VERSION ""

NS_ :

BS_:

BU_: XXX EPS

CM_ "Toyota Prius 5th Gen TSS3 test DBC v1 from user logs";
CM_ "Based on observed CAN/CAN-FD frames from uploaded logs and Toyota reference naming.";

CM_ BO_ 48 "32-byte PT/body candidate frame";
CM_ BO_ 144 "32-byte PT/body candidate frame";
CM_ BO_ 201 "32-byte PT/body candidate frame";
CM_ BO_ 213 "8-byte status candidate frame";
CM_ BO_ 215 "32-byte PT/body candidate frame";
CM_ BO_ 277 "8-byte PT/body candidate frame";
CM_ BO_ 278 "8-byte PT/body candidate frame";
CM_ BO_ 295 "8-byte PT/body candidate frame";
CM_ BO_ 392 "64-byte CAN-FD TRACK_A candidate";
CM_ BO_ 393 "64-byte CAN-FD TRACK_A candidate";
CM_ BO_ 394 "64-byte CAN-FD TRACK_A candidate";
CM_ BO_ 395 "64-byte CAN-FD TRACK_A candidate";
CM_ BO_ 396 "48-byte CAN-FD TRACK_A candidate";
CM_ BO_ 416 "48-byte CAN-FD TRACK_B candidate";
CM_ BO_ 512 "64-byte CAN-FD object/status candidate";
CM_ BO_ 513 "64-byte CAN-FD object/status candidate";

BO_ 48 PT_STATE_0x030: 32 XXX
 SG_ PT030_B00 : 0|8@0+ (1,0) [0|255] "" XXX
 SG_ PT030_B01 : 8|8@0+ (1,0) [0|255] "" XXX
 SG_ PT030_B02 : 16|8@0+ (1,0) [0|255] "" XXX
 SG_ PT030_B03 : 24|8@0+ (1,0) [0|255] "" XXX
 SG_ PT030_B04 : 32|8@0+ (1,0) [0|255] "" XXX
 SG_ PT030_B05 : 40|8@0+ (1,0) [0|255] "" XXX
 SG_ PT030_B06 : 48|8@0+ (1,0) [0|255] "" XXX
 SG_ PT030_B07 : 56|8@0+ (1,0) [0|255] "" XXX
 SG_ PT030_B08 : 64|8@0+ (1,0) [0|255] "" XXX
 SG_ PT030_B09 : 72|8@0+ (1,0) [0|255] "" XXX
 SG_ PT030_B10 : 80|8@0+ (1,0) [0|255] "" XXX
 SG_ PT030_B11 : 88|8@0+ (1,0) [0|255] "" XXX
 SG_ PT030_B12 : 96|8@0+ (1,0) [0|255] "" XXX
 SG_ PT030_B13 : 104|8@0+ (1,0) [0|255] "" XXX
 SG_ PT030_B14 : 112|8@0+ (1,0) [0|255] "" XXX
 SG_ PT030_B15 : 120|8@0+ (1,0) [0|255] "" XXX
 SG_ PT030_B16 : 128|8@0+ (1,0) [0|255] "" XXX
 SG_ PT030_B17 : 136|8@0+ (1,0) [0|255] "" XXX
 SG_ PT030_B18 : 144|8@0+ (1,0) [0|255] "" XXX
 SG_ PT030_B19 : 152|8@0+ (1,0) [0|255] "" XXX
 SG_ PT030_B20 : 160|8@0+ (1,0) [0|255] "" XXX
 SG_ PT030_B21 : 168|8@0+ (1,0) [0|255] "" XXX
 SG_ PT030_B22 : 176|8@0+ (1,0) [0|255] "" XXX
 SG_ PT030_B23 : 184|8@0+ (1,0) [0|255] "" XXX
 SG_ PT030_B24 : 192|8@0+ (1,0) [0|255] "" XXX
 SG_ PT030_B25 : 200|8@0+ (1,0) [0|255] "" XXX
 SG_ PT030_B26 : 208|8@0+ (1,0) [0|255] "" XXX
 SG_ PT030_B27 : 216|8@0+ (1,0) [0|255] "" XXX
 SG_ PT030_TAIL : 224|32@0+ (1,0) [0|4294967295] "" XXX

BO_ 144 PT_STATE_0x090: 32 XXX
 SG_ PT090_B00 : 0|8@0+ (1,0) [0|255] "" XXX
 SG_ PT090_B01 : 8|8@0+ (1,0) [0|255] "" XXX
 SG_ PT090_B02 : 16|8@0+ (1,0) [0|255] "" XXX
 SG_ PT090_B03 : 24|8@0+ (1,0) [0|255] "" XXX
 SG_ PT090_B04 : 32|8@0+ (1,0) [0|255] "" XXX
 SG_ PT090_B05 : 40|8@0+ (1,0) [0|255] "" XXX
 SG_ PT090_B06 : 48|8@0+ (1,0) [0|255] "" XXX
 SG_ PT090_B07 : 56|8@0+ (1,0) [0|255] "" XXX
 SG_ PT090_B08 : 64|8@0+ (1,0) [0|255] "" XXX
 SG_ PT090_B09 : 72|8@0+ (1,0) [0|255] "" XXX
 SG_ PT090_B10 : 80|8@0+ (1,0) [0|255] "" XXX
 SG_ PT090_B11 : 88|8@0+ (1,0) [0|255] "" XXX
 SG_ PT090_B12 : 96|8@0+ (1,0) [0|255] "" XXX
 SG_ PT090_B13 : 104|8@0+ (1,0) [0|255] "" XXX
 SG_ PT090_B14 : 112|8@0+ (1,0) [0|255] "" XXX
 SG_ PT090_B15 : 120|8@0+ (1,0) [0|255] "" XXX
 SG_ PT090_B16 : 128|8@0+ (1,0) [0|255] "" XXX
 SG_ PT090_B17 : 136|8@0+ (1,0) [0|255] "" XXX
 SG_ PT090_B18 : 144|8@0+ (1,0) [0|255] "" XXX
 SG_ PT090_B19 : 152|8@0+ (1,0) [0|255] "" XXX
 SG_ PT090_B20 : 160|8@0+ (1,0) [0|255] "" XXX
 SG_ PT090_B21 : 168|8@0+ (1,0) [0|255] "" XXX
 SG_ PT090_B22 : 176|8@0+ (1,0) [0|255] "" XXX
 SG_ PT090_B23 : 184|8@0+ (1,0) [0|255] "" XXX
 SG_ PT090_B24 : 192|8@0+ (1,0) [0|255] "" XXX
 SG_ PT090_B25 : 200|8@0+ (1,0) [0|255] "" XXX
 SG_ PT090_B26 : 208|8@0+ (1,0) [0|255] "" XXX
 SG_ PT090_B27 : 216|8@0+ (1,0) [0|255] "" XXX
 SG_ PT090_TAIL : 224|32@0+ (1,0) [0|4294967295] "" XXX

BO_ 201 PT_STATE_0x0C9: 32 XXX
 SG_ PT0C9_B00 : 0|8@0+ (1,0) [0|255] "" XXX
 SG_ PT0C9_B01 : 8|8@0+ (1,0) [0|255] "" XXX
 SG_ PT0C9_B02 : 16|8@0+ (1,0) [0|255] "" XXX
 SG_ PT0C9_B03 : 24|8@0+ (1,0) [0|255] "" XXX
 SG_ PT0C9_B04 : 32|8@0+ (1,0) [0|255] "" XXX
 SG_ PT0C9_B05 : 40|8@0+ (1,0) [0|255] "" XXX
 SG_ PT0C9_B06 : 48|8@0+ (1,0) [0|255] "" XXX
 SG_ PT0C9_B07 : 56|8@0+ (1,0) [0|255] "" XXX
 SG_ PT0C9_B08 : 64|8@0+ (1,0) [0|255] "" XXX
 SG_ PT0C9_B09 : 72|8@0+ (1,0) [0|255] "" XXX
 SG_ PT0C9_B10 : 80|8@0+ (1,0) [0|255] "" XXX
 SG_ PT0C9_B11 : 88|8@0+ (1,0) [0|255] "" XXX
 SG_ PT0C9_B12 : 96|8@0+ (1,0) [0|255] "" XXX
 SG_ PT0C9_B13 : 104|8@0+ (1,0) [0|255] "" XXX
 SG_ PT0C9_B14 : 112|8@0+ (1,0) [0|255] "" XXX
 SG_ PT0C9_B15 : 120|8@0+ (1,0) [0|255] "" XXX
 SG_ PT0C9_B16 : 128|8@0+ (1,0) [0|255] "" XXX
 SG_ PT0C9_B17 : 136|8@0+ (1,0) [0|255] "" XXX
 SG_ PT0C9_B18 : 144|8@0+ (1,0) [0|255] "" XXX
 SG_ PT0C9_B19 : 152|8@0+ (1,0) [0|255] "" XXX
 SG_ PT0C9_B20 : 160|8@0+ (1,0) [0|255] "" XXX
 SG_ PT0C9_B21 : 168|8@0+ (1,0) [0|255] "" XXX
 SG_ PT0C9_B22 : 176|8@0+ (1,0) [0|255] "" XXX
 SG_ PT0C9_B23 : 184|8@0+ (1,0) [0|255] "" XXX
 SG_ PT0C9_B24 : 192|8@0+ (1,0) [0|255] "" XXX
 SG_ PT0C9_B25 : 200|8@0+ (1,0) [0|255] "" XXX
 SG_ PT0C9_B26 : 208|8@0+ (1,0) [0|255] "" XXX
 SG_ PT0C9_B27 : 216|8@0+ (1,0) [0|255] "" XXX
 SG_ PT0C9_TAIL : 224|32@0+ (1,0) [0|4294967295] "" XXX

BO_ 213 STATUS_0x0D5: 8 XXX
 SG_ ST0D5_B0 : 0|8@0+ (1,0) [0|255] "" XXX
 SG_ ST0D5_B1 : 8|8@0+ (1,0) [0|255] "" XXX
 SG_ ST0D5_B2 : 16|8@0+ (1,0) [0|255] "" XXX
 SG_ ST0D5_B3 : 24|8@0+ (1,0) [0|255] "" XXX
 SG_ ST0D5_B4 : 32|8@0+ (1,0) [0|255] "" XXX
 SG_ ST0D5_B5 : 40|8@0+ (1,0) [0|255] "" XXX
 SG_ ST0D5_B6 : 48|8@0+ (1,0) [0|255] "" XXX
 SG_ ST0D5_B7 : 56|8@0+ (1,0) [0|255] "" XXX

BO_ 215 PT_STATE_0x0D7: 32 XXX
 SG_ PT0D7_B00 : 0|8@0+ (1,0) [0|255] "" XXX
 SG_ PT0D7_B01 : 8|8@0+ (1,0) [0|255] "" XXX
 SG_ PT0D7_B02 : 16|8@0+ (1,0) [0|255] "" XXX
 SG_ PT0D7_B03 : 24|8@0+ (1,0) [0|255] "" XXX
 SG_ PT0D7_B04 : 32|8@0+ (1,0) [0|255] "" XXX
 SG_ PT0D7_B05 : 40|8@0+ (1,0) [0|255] "" XXX
 SG_ PT0D7_B06 : 48|8@0+ (1,0) [0|255] "" XXX
 SG_ PT0D7_B07 : 56|8@0+ (1,0) [0|255] "" XXX
 SG_ PT0D7_B08 : 64|8@0+ (1,0) [0|255] "" XXX
 SG_ PT0D7_B09 : 72|8@0+ (1,0) [0|255] "" XXX
 SG_ PT0D7_B10 : 80|8@0+ (1,0) [0|255] "" XXX
 SG_ PT0D7_B11 : 88|8@0+ (1,0) [0|255] "" XXX
 SG_ PT0D7_B12 : 96|8@0+ (1,0) [0|255] "" XXX
 SG_ PT0D7_B13 : 104|8@0+ (1,0) [0|255] "" XXX
 SG_ PT0D7_B14 : 112|8@0+ (1,0) [0|255] "" XXX
 SG_ PT0D7_B15 : 120|8@0+ (1,0) [0|255] "" XXX
 SG_ PT0D7_B16 : 128|8@0+ (1,0) [0|255] "" XXX
 SG_ PT0D7_B17 : 136|8@0+ (1,0) [0|255] "" XXX
 SG_ PT0D7_B18 : 144|8@0+ (1,0) [0|255] "" XXX
 SG_ PT0D7_B19 : 152|8@0+ (1,0) [0|255] "" XXX
 SG_ PT0D7_B20 : 160|8@0+ (1,0) [0|255] "" XXX
 SG_ PT0D7_B21 : 168|8@0+ (1,0) [0|255] "" XXX
 SG_ PT0D7_B22 : 176|8@0+ (1,0) [0|255] "" XXX
 SG_ PT0D7_B23 : 184|8@0+ (1,0) [0|255] "" XXX
 SG_ PT0D7_B24 : 192|8@0+ (1,0) [0|255] "" XXX
 SG_ PT0D7_B25 : 200|8@0+ (1,0) [0|255] "" XXX
 SG_ PT0D7_B26 : 208|8@0+ (1,0) [0|255] "" XXX
 SG_ PT0D7_B27 : 216|8@0+ (1,0) [0|255] "" XXX
 SG_ PT0D7_TAIL : 224|32@0+ (1,0) [0|4294967295] "" XXX

BO_ 277 PT_STATUS_0x115: 8 XXX
 SG_ PT115_B0 : 0|8@0+ (1,0) [0|255] "" XXX
 SG_ PT115_B1 : 8|8@0+ (1,0) [0|255] "" XXX
 SG_ PT115_B2 : 16|8@0+ (1,0) [0|255] "" XXX
 SG_ PT115_B3 : 24|8@0+ (1,0) [0|255] "" XXX
 SG_ PT115_B4 : 32|8@0+ (1,0) [0|255] "" XXX
 SG_ PT115_B5 : 40|8@0+ (1,0) [0|255] "" XXX
 SG_ PT115_B6 : 48|8@0+ (1,0) [0|255] "" XXX
 SG_ PT115_B7 : 56|8@0+ (1,0) [0|255] "" XXX

BO_ 278 PT_STATUS_0x116: 8 XXX
 SG_ PT116_B0 : 0|8@0+ (1,0) [0|255] "" XXX
 SG_ PT116_B1 : 8|8@0+ (1,0) [0|255] "" XXX
 SG_ PT116_B2 : 16|8@0+ (1,0) [0|255] "" XXX
 SG_ PT116_B3 : 24|8@0+ (1,0) [0|255] "" XXX
 SG_ PT116_B4 : 32|8@0+ (1,0) [0|255] "" XXX
 SG_ PT116_B5 : 40|8@0+ (1,0) [0|255] "" XXX
 SG_ PT116_B6 : 48|8@0+ (1,0) [0|255] "" XXX
 SG_ PT116_B7 : 56|8@0+ (1,0) [0|255] "" XXX

BO_ 295 PT_STATUS_0x127: 8 XXX
 SG_ PT127_B0 : 0|8@0+ (1,0) [0|255] "" XXX
 SG_ PT127_B1 : 8|8@0+ (1,0) [0|255] "" XXX
 SG_ PT127_B2 : 16|8@0+ (1,0) [0|255] "" XXX
 SG_ PT127_B3 : 24|8@0+ (1,0) [0|255] "" XXX
 SG_ PT127_B4 : 32|8@0+ (1,0) [0|255] "" XXX
 SG_ PT127_B5 : 40|8@0+ (1,0) [0|255] "" XXX
 SG_ PT127_B6 : 48|8@0+ (1,0) [0|255] "" XXX
 SG_ PT127_B7 : 56|8@0+ (1,0) [0|255] "" XXX

BO_ 392 TRACK_A_FD_8: 64 XXX
 SG_ TRK188_B00 : 0|8@0+ (1,0) [0|255] "" XXX
 SG_ TRK188_B01 : 8|8@0+ (1,0) [0|255] "" XXX
 SG_ TRK188_B02 : 16|8@0+ (1,0) [0|255] "" XXX
 SG_ TRK188_B03 : 24|8@0+ (1,0) [0|255] "" XXX
 SG_ TRK188_B04 : 32|8@0+ (1,0) [0|255] "" XXX
 SG_ TRK188_B05 : 40|8@0+ (1,0) [0|255] "" XXX
 SG_ TRK188_B06 : 48|8@0+ (1,0) [0|255] "" XXX
 SG_ TRK188_B07 : 56|8@0+ (1,0) [0|255] "" XXX
 SG_ TRK188_B08 : 64|8@0+ (1,0) [0|255] "" XXX
 SG_ TRK188_B09 : 72|8@0+ (1,0) [0|255] "" XXX
 SG_ TRK188_B10 : 80|8@0+ (1,0) [0|255] "" XXX
 SG_ TRK188_B11 : 88|8@0+ (1,0) [0|255] "" XXX
 SG_ TRK188_B12 : 96|8@0+ (1,0) [0|255] "" XXX
 SG_ TRK188_B13 : 104|8@0+ (1,0) [0|255] "" XXX
 SG_ TRK188_B14 : 112|8@0+ (1,0) [0|255] "" XXX
 SG_ TRK188_B15 : 120|8@0+ (1,0) [0|255] "" XXX
 SG_ TRK188_B16 : 128|8@0+ (1,0) [0|255] "" XXX
 SG_ TRK188_B17 : 136|8@0+ (1,0) [0|255] "" XXX
 SG_ TRK188_B18 : 144|8@0+ (1,0) [0|255] "" XXX
 SG_ TRK188_B19 : 152|8@0+ (1,0) [0|255] "" XXX
 SG_ TRK188_B20 : 160|8@0+ (1,0) [0|255] "" XXX
 SG_ TRK188_B21 : 168|8@0+ (1,0) [0|255] "" XXX
 SG_ TRK188_B22 : 176|8@0+ (1,0) [0|255] "" XXX
 SG_ TRK188_B23 : 184|8@0+ (1,0) [0|255] "" XXX
 SG_ TRK188_B24 : 192|8@0+ (1,0) [0|255] "" XXX
 SG_ TRK188_B25 : 200|8@0+ (1,0) [0|255] "" XXX
 SG_ TRK188_B26 : 208|8@0+ (1,0) [0|255] "" XXX
 SG_ TRK188_B27 : 216|8@0+ (1,0) [0|255] "" XXX
 SG_ TRK188_B28 : 224|8@0+ (1,0) [0|255] "" XXX
 SG_ TRK188_B29 : 232|8@0+ (1,0) [0|255] "" XXX
 SG_ TRK188_B30 : 240|8@0+ (1,0) [0|255] "" XXX
 SG_ TRK188_B31 : 248|8@0+ (1,0) [0|255] "" XXX
 SG_ TRK188_B32 : 256|8@0+ (1,0) [0|255] "" XXX
 SG_ TRK188_B33 : 264|8@0+ (1,0) [0|255] "" XXX
 SG_ TRK188_B34 : 272|8@0+ (1,0) [0|255] "" XXX
 SG_ TRK188_B35 : 280|8@0+ (1,0) [0|255] "" XXX
 SG_ TRK188_B36 : 288|8@0+ (1,0) [0|255] "" XXX
 SG_ TRK188_B37 : 296|8@0+ (1,0) [0|255] "" XXX
 SG_ TRK188_B38 : 304|8@0+ (1,0) [0|255] "" XXX
 SG_ TRK188_B39 : 312|8@0+ (1,0) [0|255] "" XXX
 SG_ TRK188_B40 : 320|8@0+ (1,0) [0|255] "" XXX
 SG_ TRK188_B41 : 328|8@0+ (1,0) [0|255] "" XXX
 SG_ TRK188_B42 : 336|8@0+ (1,0) [0|255] "" XXX
 SG_ TRK188_B43 : 344|8@0+ (1,0) [0|255] "" XXX
 SG_ TRK188_B44 : 352|8@0+ (1,0) [0|255] "" XXX
 SG_ TRK188_B45 : 360|8@0+ (1,0) [0|255] "" XXX
 SG_ TRK188_B46 : 368|8@0+ (1,0) [0|255] "" XXX
 SG_ TRK188_B47 : 376|8@0+ (1,0) [0|255] "" XXX
 SG_ TRK188_B48 : 384|8@0+ (1,0) [0|255] "" XXX
 SG_ TRK188_B49 : 392|8@0+ (1,0) [0|255] "" XXX
 SG_ TRK188_B50 : 400|8@0+ (1,0) [0|255] "" XXX
 SG_ TRK188_B51 : 408|8@0+ (1,0) [0|255] "" XXX
 SG_ TRK188_B52 : 416|8@0+ (1,0) [0|255] "" XXX
 SG_ TRK188_B53 : 424|8@0+ (1,0) [0|255] "" XXX
 SG_ TRK188_B54 : 432|8@0+ (1,0) [0|255] "" XXX
 SG_ TRK188_B55 : 440|8@0+ (1,0) [0|255] "" XXX
 SG_ TRK188_B56 : 448|8@0+ (1,0) [0|255] "" XXX
 SG_ TRK188_B57 : 456|8@0+ (1,0) [0|255] "" XXX
 SG_ TRK188_B58 : 464|8@0+ (1,0) [0|255] "" XXX
 SG_ TRK188_B59 : 472|8@0+ (1,0) [0|255] "" XXX
 SG_ TRK188_TAIL : 480|32@1+ (1,0) [0|4294967295] "" XXX

BO_ 393 TRACK_A_FD_9: 64 XXX
 SG_ TRK189_PAYLOAD : 0|480@0+ (1,0) [0|0] "" XXX
 SG_ TRK189_TAIL : 480|32@1+ (1,0) [0|4294967295] "" XXX

BO_ 394 TRACK_A_FD_10: 64 XXX
 SG_ TRK18A_PAYLOAD : 0|480@0+ (1,0) [0|0] "" XXX
 SG_ TRK18A_TAIL : 480|32@1+ (1,0) [0|4294967295] "" XXX

BO_ 395 TRACK_A_FD_11: 64 XXX
 SG_ TRK18B_PAYLOAD : 0|480@0+ (1,0) [0|0] "" XXX
 SG_ TRK18B_TAIL : 480|32@1+ (1,0) [0|4294967295] "" XXX

BO_ 396 TRACK_A_FD_12: 48 XXX
 SG_ TRK18C_PAYLOAD : 0|352@0+ (1,0) [0|0] "" XXX
 SG_ TRK18C_TAIL : 352|32@0+ (1,0) [0|4294967295] "" XXX

BO_ 416 TRACK_B_FD_0: 48 XXX
 SG_ TRK1A0_PAYLOAD : 0|352@0+ (1,0) [0|0] "" XXX
 SG_ TRK1A0_TAIL : 352|32@0+ (1,0) [0|4294967295] "" XXX

BO_ 512 OBJECT_FD_0: 64 XXX
 SG_ OBJ200_PAYLOAD : 0|480@0+ (1,0) [0|0] "" XXX
 SG_ OBJ200_TAIL : 480|32@1+ (1,0) [0|4294967295] "" XXX

BO_ 513 OBJECT_FD_1: 64 XXX
 SG_ OBJ201_PAYLOAD : 0|480@0+ (1,0) [0|0] "" XXX
 SG_ OBJ201_TAIL : 480|32@1+ (1,0) [0|4294967295] "" XXX

BO_ 37 STEER_ANGLE_SENSOR: 32 XXX
 SG_ STEER_ANGLE : 3|12@0- (1.5,0) [-500|500] "deg" XXX
 SG_ STEER_FRACTION : 39|4@0- (0.1,0) [-0.7|0.7] "deg" XXX
 SG_ STEER_RATE : 35|12@0- (1,0) [-2000|2000] "deg/s" XXX

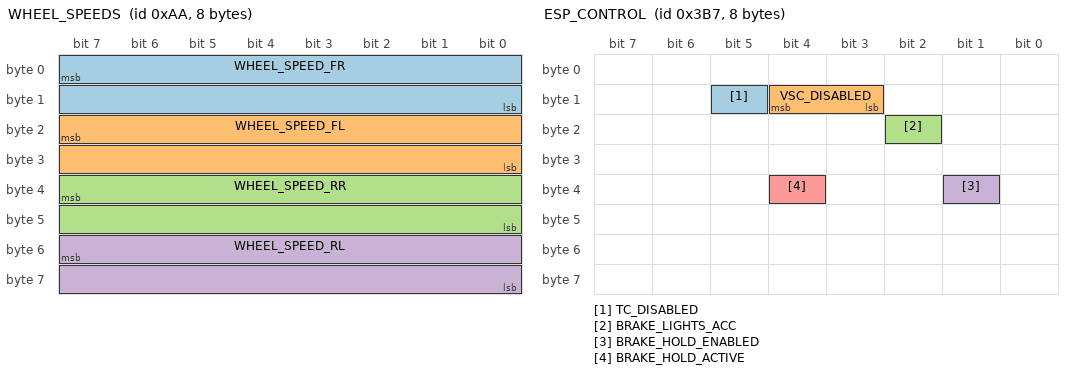
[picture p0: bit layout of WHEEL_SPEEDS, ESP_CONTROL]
BO_ 170 WHEEL_SPEEDS: 8 XXX
 SG_ WHEEL_SPEED_FR : 7|16@0+ (0.01,-67.67) [0|250] "km/h" XXX
 SG_ WHEEL_SPEED_FL : 23|16@0+ (0.01,-67.67) [0|250] "km/h" XXX
 SG_ WHEEL_SPEED_RR : 39|16@0+ (0.01,-67.67) [0|250] "km/h" XXX
 SG_ WHEEL_SPEED_RL : 55|16@0+ (0.01,-67.67) [0|250] "km/h" XXX

BO_ 951 ESP_CONTROL: 8 ESP
 SG_ TC_DISABLED : 13|1@0+ (1,0) [0|1] "" XXX
 SG_ VSC_DISABLED : 12|2@0+ (1,0) [0|1] "" XXX
 SG_ BRAKE_LIGHTS_ACC : 18|1@0+ (1,0) [0|1] "" XXX
 SG_ BRAKE_HOLD_ENABLED : 33|1@1+ (1,0) [0|1] "" XXX
 SG_ BRAKE_HOLD_ACTIVE : 36|1@0+ (1,0) [0|1] "" XXX

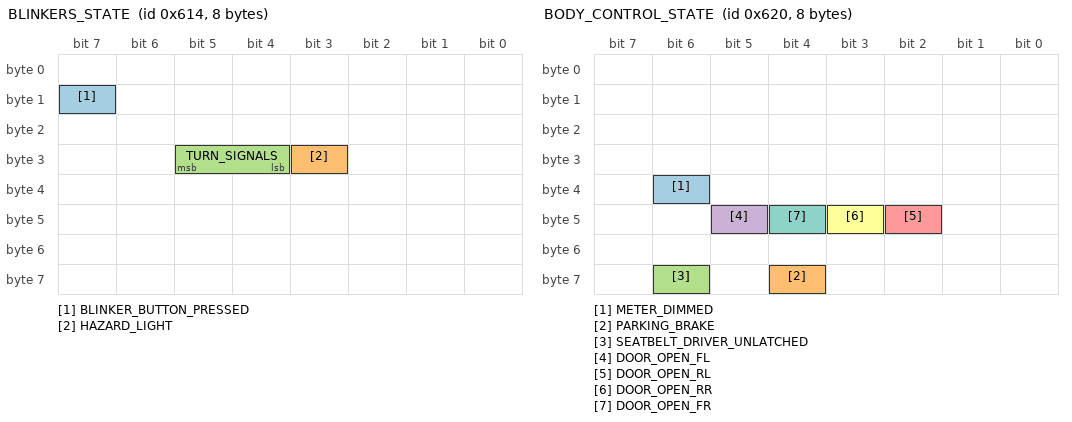
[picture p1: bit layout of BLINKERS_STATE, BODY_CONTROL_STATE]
BO_ 1556 BLINKERS_STATE: 8 XXX
 SG_ BLINKER_BUTTON_PRESSED : 15|1@0+ (1,0) [0|1] "" XXX
 SG_ HAZARD_LIGHT : 27|1@0+ (1,0) [0|1] "" XXX
 SG_ TURN_SIGNALS : 29|2@0+ (1,0) [0|3] "" XXX

BO_ 1526 PCM_CRUISE_5TH: 8 XXX
 SG_ CRUISE_BYTE : 63|8@0+ (1,0) [0|255] "" XXX

BO_ 1568 BODY_CONTROL_STATE: 8 XXX
 SG_ METER_DIMMED : 38|1@0+ (1,0) [0|1] "" XXX
 SG_ PARKING_BRAKE : 60|1@0+ (1,0) [0|1] "" XXX
 SG_ SEATBELT_DRIVER_UNLATCHED : 62|1@0+ (1,0) [0|1] "" XXX
 SG_ DOOR_OPEN_FL : 45|1@0+ (1,0) [0|1] "" XXX
 SG_ DOOR_OPEN_RL : 42|1@0+ (1,0) [0|1] "" XXX
 SG_ DOOR_OPEN_RR : 43|1@0+ (1,0) [0|1] "" XXX
 SG_ DOOR_OPEN_FR : 44|1@0+ (1,0) [0|1] "" XXX
